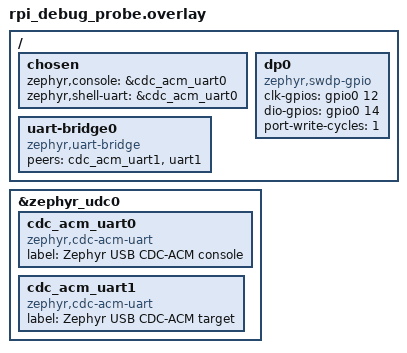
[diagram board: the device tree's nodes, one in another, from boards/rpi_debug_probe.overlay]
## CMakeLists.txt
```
# Copyright (c) 2023 Nordic Semiconductor ASA
# SPDX-License-Identifier: Apache-2.0

cmake_minimum_required(VERSION 3.28.0)
find_package(Zephyr REQUIRED HINTS $ENV{ZEPHYR_BASE})
project(dap)

include(${ZEPHYR_BASE}/samples/subsys/usb/common/common.cmake)
FILE(GLOB app_sources src/*.c)
target_sources(app PRIVATE ${app_sources})
```

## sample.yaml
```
sample:
  name: DAP USB
tests:
  sample.dap.bulk:
    build_only: true
    depends_on:
      - arduino_gpio
      - usbd
    platform_allow:
      - nrf52840dk/nrf52840
      - frdm_k64f
      - nucleo_c071rb
      - rpi_debug_probe
    tags: dap
```

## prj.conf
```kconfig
CONFIG_USB_DEVICE_STACK_NEXT=y
CONFIG_CDC_ACM_SERIAL_INITIALIZE_AT_BOOT=n
CONFIG_SAMPLE_USBD_PRODUCT="Zephyr CMSIS-DAP"
CONFIG_SAMPLE_USBD_PID=0x0204
CONFIG_SAMPLE_USBD_20_EXTENSION_DESC=y

CONFIG_STDOUT_CONSOLE=y
CONFIG_SERIAL=y
CONFIG_UART_INTERRUPT_DRIVEN=y
CONFIG_UART_LINE_CTRL=y

CONFIG_LOG=y
CONFIG_LOG_DEFAULT_LEVEL=2

CONFIG_DAP_LOG_LEVEL_INF=y
CONFIG_DP_DRIVER_LOG_LEVEL_INF=y
CONFIG_DAP=y
CONFIG_DAP_BACKEND_USB=y
CONFIG_GPIO=y
```

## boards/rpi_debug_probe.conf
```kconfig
CONFIG_USBD_CDC_ACM_LOG_LEVEL_OFF=y
```

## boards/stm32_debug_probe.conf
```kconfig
CONFIG_MAIN_STACK_SIZE=768
CONFIG_SYSTEM_WORKQUEUE_STACK_SIZE=768
CONFIG_LOG_BUFFER_SIZE=128
CONFIG_USBD_CDC_ACM_LOG_LEVEL_OFF=y
```

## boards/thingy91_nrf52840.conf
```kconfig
CONFIG_USB_DEVICE_REMOTE_WAKEUP=n
CONFIG_USB_MAX_POWER=250
CONFIG_CMSIS_DAP_DEVICE_VENDOR="Nordic Semiconductor"
CONFIG_CMSIS_DAP_DEVICE_NAME="nrf9160_xxaa"
```

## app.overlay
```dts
/*
 * Copyright (c) 2023 Nordic Semiconductor ASA
 *
 * SPDX-License-Identifier: Apache-2.0
 */

/ {
	dp0 {
		compatible = "zephyr,swdp-gpio";

		clk-gpios = <&arduino_header 10 GPIO_ACTIVE_HIGH>;	/* D4 */
		noe-gpios = <&arduino_header 9 GPIO_ACTIVE_HIGH>;	/* D3 */
		dio-gpios = <&arduino_header 8 GPIO_PULL_UP>;		/* D2 */
		port-write-cycles = <2>;
		status = "okay";
	};
};
```

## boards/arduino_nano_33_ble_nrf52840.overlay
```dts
/*
 * Copyright (c) 2023 Nordic Semiconductor ASA
 *
 * SPDX-License-Identifier: Apache-2.0
 */

/ {
	dp0 {
		compatible = "zephyr,swdp-gpio";
		status = "okay";

		clk-gpios = <&gpio1 2 GPIO_ACTIVE_HIGH>;	/* D10 */
		noe-gpios = <&gpio1 14 GPIO_ACTIVE_HIGH>;	/* D6 */
		dio-gpios = <&gpio0 27 GPIO_PULL_UP>;		/* D9 */
		reset-gpios = <&gpio1 13 GPIO_ACTIVE_HIGH>;	/* D5 */
		port-write-cycles = <2>;
	};
};
```

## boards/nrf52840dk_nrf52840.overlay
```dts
/*
 * Copyright (c) 2023 Nordic Semiconductor ASA
 *
 * SPDX-License-Identifier: Apache-2.0
 */

/ {
	dp0 {
		compatible = "zephyr,swdp-gpio";
		clk-gpios = <&arduino_header 10 GPIO_ACTIVE_HIGH>;	/* D4 */
		dio-gpios = <&arduino_header 8 GPIO_PULL_UP>;		/* D2 */
		dout-gpios = <&arduino_header 9 GPIO_ACTIVE_HIGH>;	/* D3 */
		dnoe-gpios = <&arduino_header 12 GPIO_ACTIVE_HIGH>;	/* D6 */
		noe-gpios = <&arduino_header 11 GPIO_ACTIVE_HIGH>;	/* D5 */
		reset-gpios = <&arduino_header 13 GPIO_ACTIVE_HIGH>;	/* D7 */
		port-write-cycles = <2>;
		status = "okay";
	};
};
```

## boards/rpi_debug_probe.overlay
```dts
/*
 * Copyright The Zephyr Project Contributors
 *
 * SPDX-License-Identifier: Apache-2.0
 */

/ {
	chosen {
		zephyr,console = &cdc_acm_uart0;
		zephyr,shell-uart = &cdc_acm_uart0;
	};

	uart-bridge0 {
		compatible = "zephyr,uart-bridge";
		peers = <&cdc_acm_uart1 &uart1>;
	};

	dp0 {
		compatible = "zephyr,swdp-gpio";
		clk-gpios = <&gpio0 12 GPIO_ACTIVE_HIGH>;
		dio-gpios = <&gpio0 14 GPIO_PULL_UP>;
		port-write-cycles = <1>;
		status = "okay";
	};
};

&zephyr_udc0 {
	cdc_acm_uart0: cdc_acm_uart0 {
		compatible = "zephyr,cdc-acm-uart";
		label = "Zephyr USB CDC-ACM console";
	};

	cdc_acm_uart1: cdc_acm_uart1 {
		compatible = "zephyr,cdc-acm-uart";
		label = "Zephyr USB CDC-ACM target";
	};
};
```

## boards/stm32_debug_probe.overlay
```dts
/*
 * Copyright (c) 2026 Muhammad Waleed Badar
 *
 * SPDX-License-Identifier: Apache-2.0
 */

/ {
	chosen {
		zephyr,console = &cdc_acm_uart0;
		zephyr,shell-uart = &cdc_acm_uart0;
	};

	uart-bridge0 {
		compatible = "zephyr,uart-bridge";
		peers = <&cdc_acm_uart1 &usart2>;
	};

	dp0 {
		compatible = "zephyr,swdp-gpio";
		status = "okay";
		clk-gpios = <&gpioa 3 GPIO_ACTIVE_HIGH>;
		dio-gpios = <&gpioa 4 GPIO_PULL_UP>;
		port-write-cycles = <1>;
	};
};

&zephyr_udc0 {
	cdc_acm_uart0: cdc-acm-uart0 {
		compatible = "zephyr,cdc-acm-uart";
		label = "Zephyr USB CDC-ACM console";
	};

	cdc_acm_uart1: cdc-acm-uart1 {
		compatible = "zephyr,cdc-acm-uart";
		label = "Zephyr USB CDC-ACM target";
	};
};
```

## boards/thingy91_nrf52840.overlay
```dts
/*
 * Copyright (c) 2023 Nordic Semiconductor ASA
 *
 * SPDX-License-Identifier: Apache-2.0
 */

/ {
	dp0 {
		compatible = "zephyr,swdp-gpio";
		status = "okay";
		clk-gpios = <&gpio1 5 GPIO_ACTIVE_HIGH>;
		dio-gpios = <&gpio0 14 GPIO_ACTIVE_HIGH>;
		noe-gpios = <&gpio0 17 GPIO_ACTIVE_HIGH>;
		port-write-cycles = <2>;
	};
};
```

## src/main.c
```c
/*
 * Copyright (c) 2023 Nordic Semiconductor ASA
 *
 * SPDX-License-Identifier: Apache-2.0
 */

#include <sample_usbd.h>

#include <zephyr/kernel.h>
#include <zephyr/device.h>
#include <zephyr/sys/byteorder.h>
#include <zephyr/usb/usbd.h>
#include <zephyr/usb/bos.h>
#include <zephyr/usb/msos_desc.h>
#include <zephyr/dap/dap_link.h>

#include <zephyr/logging/log.h>
LOG_MODULE_REGISTER(dap_sample, LOG_LEVEL_INF);

#include "webusb.h"
#include "msosv2.h"

DAP_LINK_CONTEXT_DEFINE(sample_dap_ctx, DEVICE_DT_GET_ONE(zephyr_swdp_gpio));

int main(void)
{
	struct usbd_context *sample_usbd;
	int ret;

	ret = dap_link_init(&sample_dap_ctx);
	if (ret) {
		LOG_ERR("Failed to initialize DAP controller, %d", ret);
		return ret;
	}

	ret = dap_link_backend_usb_init(&sample_dap_ctx);
	if (ret) {
		LOG_ERR("Failed to initialize DAP Link USB backend, %d", ret);
		return ret;
	}

	sample_usbd = sample_usbd_setup_device(NULL);
	if (sample_usbd == NULL) {
		LOG_ERR("Failed to setup USB device");
		return -ENODEV;
	}

	ret = usbd_add_descriptor(sample_usbd, &bos_vreq_msosv2);
	if (ret) {
		LOG_ERR("Failed to add MSOSv2 capability descriptor");
		return ret;
	}

	ret = usbd_add_descriptor(sample_usbd, &bos_vreq_webusb);
	if (ret) {
		LOG_ERR("Failed to add WebUSB capability descriptor");
		return ret;
	}

	ret = usbd_init(sample_usbd);
	if (ret) {
		LOG_ERR("Failed to initialize device support");
		return ret;
	}

	ret = usbd_enable(sample_usbd);
	if (ret) {
		LOG_ERR("Failed to enable device support");
		return ret;
	}

	return 0;
}
```

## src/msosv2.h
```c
/*
 * Copyright (c) 2016-2019 Intel Corporation
 * Copyright (c) 2023-2024 Nordic Semiconductor ASA
 *
 * SPDX-License-Identifier: Apache-2.0
 */

#ifndef ZEPHYR_INCLUDE_MSOSV2_DESCRIPTOR_H
#define ZEPHYR_INCLUDE_MSOSV2_DESCRIPTOR_H

/*
 * Microsoft OS 2.0 platform capability and Microsoft OS 2.0 descriptor set.
 * See Microsoft OS 2.0 Descriptors Specification for reference.
 */

#define SAMPLE_MSOS2_VENDOR_CODE	0x02U
/* Windows version (10)*/
#define SAMPLE_MSOS2_OS_VERSION		0x0A000000UL

/* {CDB3B5AD-293B-4663-AA36-1AAE46463776} */
#define CMSIS_DAP_V2_DEVICE_INTERFACE_GUID \
	'{', 0x00, 'C', 0x00, 'D', 0x00, 'B', 0x00, '3', 0x00, 'B', 0x00, \
	'5', 0x00, 'A', 0x00, 'D', 0x00, '-', 0x00, '2', 0x00, '9', 0x00, \
	'3', 0x00, 'B', 0x00, '-', 0x00, '4', 0x00, '6', 0x00, '6', 0x00, \
	'3', 0x00, '-', 0x00, 'A', 0x00, 'A', 0x00, '3', 0x00, '6', 0x00, \
	'-', 0x00, '1', 0x00, 'A', 0x00, 'A', 0x00, 'E', 0x00, '4', 0x00, \
	'6', 0x00, '4', 0x00, '6', 0x00, '3', 0x00, '7', 0x00, '7', 0x00, \
	'6', 0x00, '}', 0x00, 0x00, 0x00, 0x00, 0x00

#define CDC_ACM_DESCRIPTOR_LENGTH 160

struct msosv2_descriptor {
	struct msosv2_descriptor_set_header header;
#if defined(CONFIG_USBD_CDC_ACM_CLASS)
	/*
	 * The composition of this descriptor is specific to the WebUSB example
	 * in its default configuration. If you use it for your application or
	 * change the configuration, you may need to modify this descriptor for
	 * your USB device. The following only covers the case where the CDC
	 * ACM implementation is enabled, and there is only one CDC ACM UART
	 * instance, and the CDC ACM communication interface is the first in
	 * the configuration.
	 */
	struct msosv2_function_subset_header subset_header;
#endif
	struct msosv2_compatible_id compatible_id;
	struct msosv2_guids_property guids_property;
} __packed;

static struct msosv2_descriptor msosv2_desc = {
	.header = {
		.wLength = sizeof(struct msosv2_descriptor_set_header),
		.wDescriptorType = MS_OS_20_SET_HEADER_DESCRIPTOR,
		.dwWindowsVersion = sys_cpu_to_le32(SAMPLE_MSOS2_OS_VERSION),
		.wTotalLength = sizeof(msosv2_desc),
	},
#if defined(CONFIG_USBD_CDC_ACM_CLASS)
	.subset_header = {
		.wLength = sizeof(struct msosv2_function_subset_header),
		.wDescriptorType = MS_OS_20_SUBSET_HEADER_FUNCTION,
		.bFirstInterface = 0,
		.wSubsetLength = CDC_ACM_DESCRIPTOR_LENGTH,
	},
#endif
	.compatible_id = {
		.wLength = sizeof(struct msosv2_compatible_id),
		.wDescriptorType = MS_OS_20_FEATURE_COMPATIBLE_ID,
		.CompatibleID = {'W', 'I', 'N', 'U', 'S', 'B', 0x00, 0x00},
	},
	.guids_property = {
		.wLength = sizeof(struct msosv2_guids_property),
		.wDescriptorType = MS_OS_20_FEATURE_REG_PROPERTY,
		.wPropertyDataType = MS_OS_20_PROPERTY_DATA_REG_MULTI_SZ,
		.wPropertyNameLength = 42,
		.PropertyName = {DEVICE_INTERFACE_GUIDS_PROPERTY_NAME},
		.wPropertyDataLength = 80,
		.bPropertyData = {CMSIS_DAP_V2_DEVICE_INTERFACE_GUID},
	},
};

struct bos_msosv2_descriptor {
	struct usb_bos_platform_descriptor platform;
	struct usb_bos_capability_msos cap;
} __packed;

struct bos_msosv2_descriptor bos_msosv2_desc = {
	/*
	 * Microsoft OS 2.0 Platform Capability Descriptor,
	 * see Microsoft OS 2.0 Descriptors Specification
	 */
	.platform = {
		.bLength = sizeof(struct usb_bos_platform_descriptor)
			 + sizeof(struct usb_bos_capability_msos),
		.bDescriptorType = USB_DESC_DEVICE_CAPABILITY,
		.bDevCapabilityType = USB_BOS_CAPABILITY_PLATFORM,
		.bReserved = 0,
		/* Microsoft OS 2.0 descriptor platform capability UUID
		 * D8DD60DF-4589-4CC7-9CD2-659D9E648A9F
		 */
		.PlatformCapabilityUUID = {
			0xDF, 0x60, 0xDD, 0xD8,
			0x89, 0x45,
			0xC7, 0x4C,
			0x9C, 0xD2,
			0x65, 0x9D, 0x9E, 0x64, 0x8A, 0x9F,
		},
	},
	.cap = {
		.dwWindowsVersion = sys_cpu_to_le32(SAMPLE_MSOS2_OS_VERSION),
		.wMSOSDescriptorSetTotalLength = sys_cpu_to_le16(sizeof(msosv2_desc)),
		.bMS_VendorCode = SAMPLE_MSOS2_VENDOR_CODE,
		.bAltEnumCode = 0x00
	},
};

static struct net_buf *msosv2_to_host_cb(const struct usbd_context *const ctx,
					 const struct usb_setup_packet *const setup)
{
	LOG_INF("Vendor callback to host");

	if (setup->bRequest == SAMPLE_MSOS2_VENDOR_CODE &&
	    setup->wIndex == MS_OS_20_DESCRIPTOR_INDEX) {
		struct net_buf *buf;
		uint16_t len = MIN(setup->wLength, sizeof(msosv2_desc));

		LOG_INF("Get MS OS 2.0 Descriptor Set");

		buf = usbd_ep_ctrl_data_in_alloc(ctx, len);
		if (buf == NULL) {
			return NULL;
		}

		net_buf_add_mem(buf, &msosv2_desc, len);

		return buf;
	}

	return NULL;
}

USBD_DESC_BOS_VREQ_DEFINE(bos_vreq_msosv2, sizeof(bos_msosv2_desc), &bos_msosv2_desc,
			  SAMPLE_MSOS2_VENDOR_CODE, msosv2_to_host_cb, NULL);

#endif /* ZEPHYR_INCLUDE_MSOSV2_DESCRIPTOR_H */
```

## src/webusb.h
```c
/*
 * Copyright (c) 2016-2019 Intel Corporation
 * Copyright (c) 2023-2024 Nordic Semiconductor ASA
 *
 * SPDX-License-Identifier: Apache-2.0
 */

#ifndef ZEPHYR_INCLUDE_WEBUSB_DESCRIPTOR_H
#define ZEPHYR_INCLUDE_WEBUSB_DESCRIPTOR_H

/*
 * WebUSB platform capability and WebUSB URL descriptor.
 * See https://wicg.github.io/webusb for reference.
 */

#define WEBUSB_REQ_GET_URL		0x02U
#define WEBUSB_DESC_TYPE_URL		0x03U
#define WEBUSB_URL_PREFIX_HTTP		0x00U
#define WEBUSB_URL_PREFIX_HTTPS		0x01U

#define SAMPLE_WEBUSB_VENDOR_CODE	0x01U
#define SAMPLE_WEBUSB_LANDING_PAGE	0x01U

struct usb_bos_webusb_desc {
	struct usb_bos_platform_descriptor platform;
	struct usb_bos_capability_webusb cap;
} __packed;

static const struct usb_bos_webusb_desc bos_cap_webusb = {
	/* WebUSB Platform Capability Descriptor:
	 * https://wicg.github.io/webusb/#webusb-platform-capability-descriptor
	 */
	.platform = {
		.bLength = sizeof(struct usb_bos_platform_descriptor)
			 + sizeof(struct usb_bos_capability_webusb),
		.bDescriptorType = USB_DESC_DEVICE_CAPABILITY,
		.bDevCapabilityType = USB_BOS_CAPABILITY_PLATFORM,
		.bReserved = 0,
		/* WebUSB Platform Capability UUID
		 * 3408b638-09a9-47a0-8bfd-a0768815b665
		 */
		.PlatformCapabilityUUID = {
			0x38, 0xB6, 0x08, 0x34,
			0xA9, 0x09,
			0xA0, 0x47,
			0x8B, 0xFD,
			0xA0, 0x76, 0x88, 0x15, 0xB6, 0x65,
		},
	},
	.cap = {
		.bcdVersion = sys_cpu_to_le16(0x0100),
		.bVendorCode = SAMPLE_WEBUSB_VENDOR_CODE,
		.iLandingPage = SAMPLE_WEBUSB_LANDING_PAGE
	}
};

/* WebUSB URL Descriptor, see https://wicg.github.io/webusb/#webusb-descriptors */
static const uint8_t webusb_origin_url[] = {
	/* bLength, bDescriptorType, bScheme, UTF-8 encoded URL */
	0x24, WEBUSB_DESC_TYPE_URL, WEBUSB_URL_PREFIX_HTTPS,
	'w', 'w', 'w', '.',
	'z', 'e', 'p', 'h', 'y', 'r', 'p', 'r', 'o', 'j', 'e', 'c', 't', '.',
	'o', 'r', 'g', '/',
};

static struct net_buf *webusb_to_host_cb(const struct usbd_context *const ctx,
					 const struct usb_setup_packet *const setup)
{
	LOG_INF("Vendor callback to host");

	if (setup->wIndex == WEBUSB_REQ_GET_URL) {
		struct net_buf *buf;
		uint16_t len;
		uint8_t index = USB_GET_DESCRIPTOR_INDEX(setup->wValue);

		if (index != SAMPLE_WEBUSB_LANDING_PAGE) {
			return NULL;
		}

		len = MIN(setup->wLength, sizeof(webusb_origin_url));
		buf = usbd_ep_ctrl_data_in_alloc(ctx, len);
		if (buf == NULL) {
			return NULL;
		}

		LOG_INF("Get URL request, index %u", index);
		net_buf_add_mem(buf, &webusb_origin_url, len);

		return buf;
	}

	return NULL;
}

USBD_DESC_BOS_VREQ_DEFINE(bos_vreq_webusb, sizeof(bos_cap_webusb), &bos_cap_webusb,
			  SAMPLE_WEBUSB_VENDOR_CODE, webusb_to_host_cb, NULL);

#endif /* ZEPHYR_INCLUDE_WEBUSB_DESCRIPTOR_H */
```
